# STMP3770 register map
Vendor: Freescale Semiconductor (NXP); Series: STMP37xx; File version: 1.0
CPU: other r0p0, little endian, no MPU, no FPU, 2 interrupt priority bits
Registers are 32-bit, read-write, reset 0x0 unless marked. A register's access mark holds for its fields unless they carry their own. Offsets are from the block's base; [hi:lo] are bit positions; {n}, {i} and the like mark numbered series; 'fields as' and 'values as' point back to an identical list.

## APBX — AHB-to-APBX 桥 DMA 控制器(为音频、UARTAPP、I2C、LRADC 等低速外设提供 DMA 通道)
Base 0x80024000
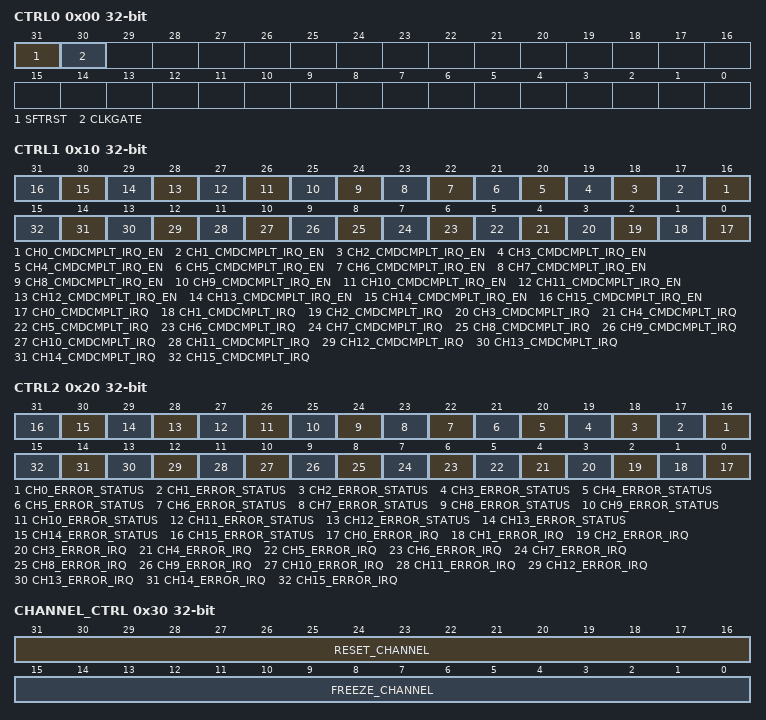
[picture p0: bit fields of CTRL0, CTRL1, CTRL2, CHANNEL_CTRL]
0x00 CTRL0 — AHB to APBX Bridge Control Register 0
  [31] SFTRST — 软复位控制位，写1复位本模块，写0恢复正常运行。复位后所有寄存器回到默认值。
  [30] CLKGATE — 时钟门控控制位，写1关闭模块时钟以节省功耗，配置状态保持。写0恢复正常时钟供应。
0x10 CTRL1 — AHB to APBX Bridge Control Register 1
  [n+16] CH{n}_CMDCMPLT_IRQ_EN (n=0..15) — Ch{n} Cmdcmplt Irq En，1位读写字段。
  [n] CH{n}_CMDCMPLT_IRQ (n=0..15) — Ch{n} Cmdcmplt Irq，1位读写字段。
0x20 CTRL2 — AHB to APBX Bridge Control and Status Register 2
  [n+16] CH{n}_ERROR_STATUS (n=0..15) — Ch{n} Error Status，1位读写字段。
    0=TERMINATION; 1=BUS_ERROR
  [n] CH{n}_ERROR_IRQ (n=0..15) — Ch{n} Error Irq，1位读写字段。
0x30 CHANNEL_CTRL — AHB to APBX Bridge Channel Register
  [31:16] RESET_CHANNEL — Reset Channel，16位读写字段。
    1=AUDIOIN; 2=AUDIOOUT; 4=SPDIF_TX; 8=I2C; 16=SAIF1; 32=DRI; 64=IRDA_RX; 128=IRDA_TX; 0x100=UART1_RX; 0x200=UART1_TX; 0x400=SAIF2
  [15:0] FREEZE_CHANNEL — Freeze Channel，16位读写字段。
    values as RESET_CHANNEL
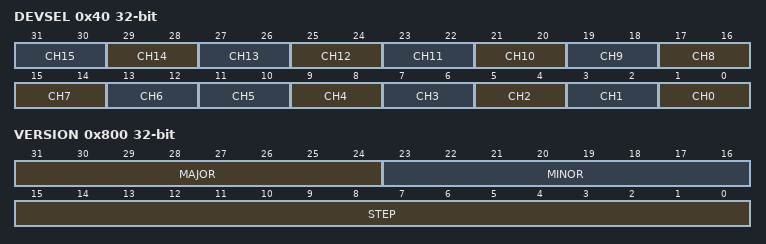
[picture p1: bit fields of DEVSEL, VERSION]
0x40 DEVSEL — AHB to APBX DMA Device Assignment Register
  [2n+1:2n] CH{n} (n=8..15) — Ch{n}，2位读写字段。
  [15:14] CH7 — Ch7，2位读写字段。
    0=USE_I2C1; 1=USE_IRDA
  [13:12] CH6 — Ch6，2位读写字段。
    0=USE_SAIF1; 1=USE_IRDA
  [2n+1:2n] CH{n} (n=0..5) — Ch{n}，2位读写字段。
0x800 VERSION ro — APBX Bridge Version Register
  [31:24] MAJOR — Major，8位读写字段。
  [23:16] MINOR — Minor，8位读写字段。
  [15:0] STEP — Step，16位读写字段。

## OCOTP — 片上一次性可编程熔丝(OCOTP,存储芯片 ID、ROM 配置、密钥与硬件能力位)
Base 0x8002C000
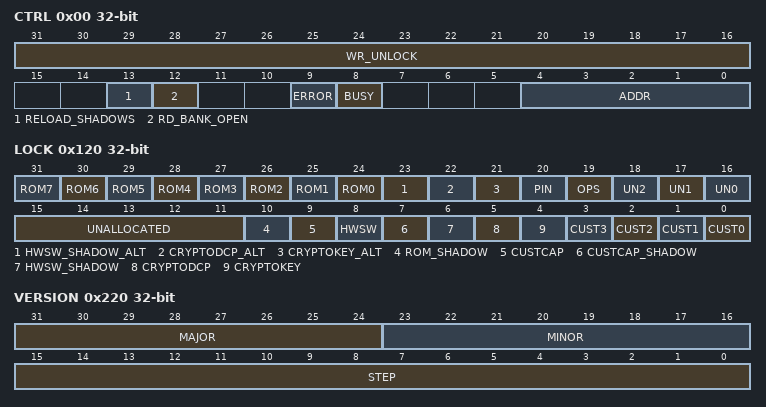
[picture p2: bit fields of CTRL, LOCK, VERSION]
0x00 CTRL — OTP Controller Control Register
  [31:16] WR_UNLOCK — Wr Unlock，16位读写字段。
    0x3E77=KEY
  [13] RELOAD_SHADOWS — Reload Shadows，1位读写字段。
  [12] RD_BANK_OPEN — Rd Bank Open，1位读写字段。
  [9] ERROR — Error，1位读写字段。
  [8] BUSY — Busy，1位读写字段。
  [4:0] ADDR — Addr，5位读写字段。
0x10 DATA — OTP Controller Write Data Register
  [31:0] DATA — 数据寄存器，写操作将数据写入发送FIFO，读操作从接收FIFO取出数据。
{0x20+0x10*i} CUST{i} (i=0..3)
  [31:0] BITS — Bits，32位读写字段。
{0x60+0x10*i} CRYPTO{i} (i=0..3)
  [31:0] BITS — Bits，32位读写字段。
{0xA0+0x10*i} HWCAP{i} (i=0..5)
  [31:0] BITS — Bits，32位读写字段。
0x100 SWCAP — SW Capability Shadow Register
  [31:0] BITS — Bits，32位读写字段。
0x110 CUSTCAP — Customer Capability Shadow Register
  [31:0] BITS — Bits，32位读写字段。
0x120 LOCK — LOCK Shadow Register OTP Bank 2 Word 0
  [n+24] ROM{n} (n=0..7) — Rom{n}，1位读写字段。
  [23] HWSW_SHADOW_ALT — Hwsw Shadow Alt，1位读写字段。
  [22] CRYPTODCP_ALT — Cryptodcp Alt，1位读写字段。
  [21] CRYPTOKEY_ALT — Cryptokey Alt，1位读写字段。
  [20] PIN — Pin，1位读写字段。
  [19] OPS — Ops，1位读写字段。
  [18] UN2 — Un2，1位读写字段。
  [17] UN1 — Un1，1位读写字段。
  [16] UN0 — Un0，1位读写字段。
  [15:11] UNALLOCATED — Unallocated，5位读写字段。
  [10] ROM_SHADOW — Rom Shadow，1位读写字段。
  [9] CUSTCAP — Custcap，1位读写字段。
  [8] HWSW — Hwsw，1位读写字段。
  [7] CUSTCAP_SHADOW — Custcap Shadow，1位读写字段。
  [6] HWSW_SHADOW — Hwsw Shadow，1位读写字段。
  [5] CRYPTODCP — Cryptodcp，1位读写字段。
  [4] CRYPTOKEY — Cryptokey，1位读写字段。
  [n] CUST{n} (n=0..3) — Cust{n}，1位读写字段。
{0x130+0x10*i} OPS{i} (i=0..3)
  [31:0] BITS — Bits，32位读写字段。
{0x170+0x10*i} UN{i} (i=0..2)
  [31:0] BITS — Bits，32位读写字段。
{0x1A0+0x10*i} ROM{i} (i=0..7)
  [31:0] BITS — Bits，32位读写字段。
0x220 VERSION ro — OTP Controller Version Register
  [31:24] MAJOR — Major，8位读写字段。
  [23:16] MINOR — Minor，8位读写字段。
  [15:0] STEP — Step，16位读写字段。

## SAIF1 — 串行音频接口 1(SAIF,I2S 风格音频数据收发)
Base 0x80042000
Same registers: SAIF2 0x80046000
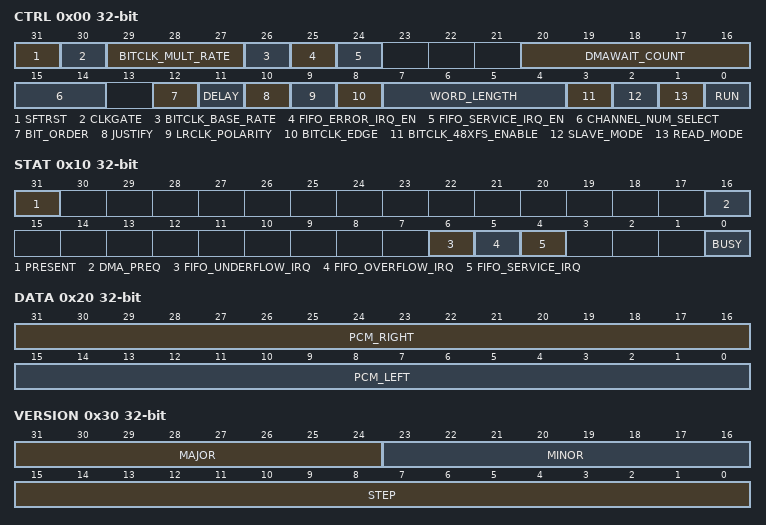
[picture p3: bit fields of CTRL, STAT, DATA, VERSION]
0x00 CTRL — SAIF Control Register
  [31] SFTRST — 软复位控制位，写1复位本模块，写0恢复正常运行。复位后所有寄存器回到默认值。
  [30] CLKGATE — 时钟门控控制位，写1关闭模块时钟以节省功耗，配置状态保持。写0恢复正常时钟供应。
  [29:27] BITCLK_MULT_RATE — 位时钟倍频速率选择，在基准速率上配置倍频系数。
  [26] BITCLK_BASE_RATE — 位时钟基准速率选择，配置 SAIF 位时钟的基准分频值。
  [25] FIFO_ERROR_IRQ_EN — FIFO 错误中断使能，置位时允许 FIFO 上溢/下溢触发中断。
  [24] FIFO_SERVICE_IRQ_EN — FIFO 服务中断使能，置位时允许 FIFO 触发服务请求中断。
  [20:16] DMAWAIT_COUNT — DMA 等待计数值，DMA 请求的等待周期数。
  [15:14] CHANNEL_NUM_SELECT — 声道数选择，配置 I2S 接口的音频声道数量。
  [12] BIT_ORDER — 位顺序控制，0=MSB 先发送，1=LSB 先发送。
  [11] DELAY — 数据延迟控制，配置数据相对于帧同步信号的延迟周期数。
  [10] JUSTIFY — 数据对齐方式选择，控制数据在帧内的对齐位置（左对齐/右对齐/I2S）。
  [9] LRCLK_POLARITY — 左右声道时钟极性控制，定义帧同步信号的极性。
  [8] BITCLK_EDGE — 位时钟边沿选择，决定数据在哪个时钟边沿驱动和采样。
  [7:4] WORD_LENGTH — 数据字长选择，0=16位，1=20位，2=24位，3=32位。
  [3] BITCLK_48XFS_ENABLE — 位时钟 48x 帧同步使能，置位时位时钟频率为帧同步的 48 倍。
  [2] SLAVE_MODE — 主从模式选择，0=主机模式（SAIF 产生位时钟和帧时钟），1=从机模式（外部提供时钟）。
  [1] READ_MODE — I2S 读模式选择，置位时 SAIF 从外部读取数据（接收模式），清零时发送数据（发送模式）。
  [0] RUN — 运行使能位，写1启动模块运行，写0停止。DMA操作时硬件自动置位。
0x10 STAT — SAIF Status Register
  [31] PRESENT — SAIF 模块存在标志，只读。1=SAIF 模块在本芯片中存在。
  [16] DMA_PREQ — DMA 请求状态，反映当前 DMA 请求线的状态。只读。
  [6] FIFO_UNDERFLOW_IRQ — FIFO 下溢中断状态，置位表示发送 FIFO 发生下溢。写 1 清零。
  [5] FIFO_OVERFLOW_IRQ — FIFO 上溢中断状态，置位表示接收 FIFO 发生上溢。写 1 清零。
  [4] FIFO_SERVICE_IRQ — FIFO 服务中断状态，置位表示 FIFO 需要服务（可从 DATA 读写数据）。写 1 清零。
  [0] BUSY — SAIF 忙状态指示，置位表示 SAIF 正在数据发送或接收中。
0x20 DATA — SAIF Data Register
  [31:16] PCM_RIGHT — 右声道 PCM 数据，存放 I2S 右声道音频采样数据（低 16 位）。
  [15:0] PCM_LEFT — 左声道 PCM 数据，存放 I2S 左声道音频采样数据（高 16 位）。
0x30 VERSION ro — SAIF Version Register
  [31:24] MAJOR — SAIF 模块主版本号，只读。
  [23:16] MINOR — SAIF 模块次版本号，只读。
  [15:0] STEP — SAIF 模块修订步进号，只读。
